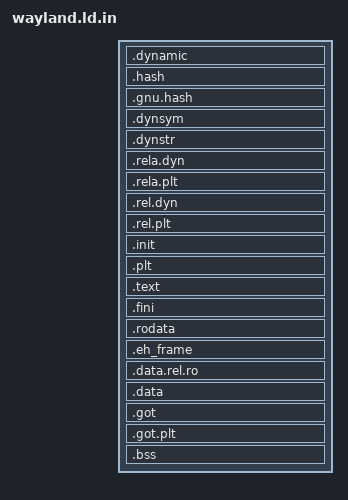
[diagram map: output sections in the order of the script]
/*
 * Linker script template for the CactOS Wayland libraries.  meson substitutes
 * @base@ per library (the loader's library slab; the whole address map is in
 * CactLibc ldso/ldso.h).  CactOS maps every image at its link-time address
 * (bias 0), so each base only has to be disjoint from every other image and
 * below the kernel mmap window (0x80000000).
 */

SECTIONS {
    . = @base@;

    .dynamic   : { *(.dynamic) }
    .hash      : { *(.hash) }
    .gnu.hash  : { *(.gnu.hash) }
    .dynsym    : { *(.dynsym) }
    .dynstr    : { *(.dynstr) }
    .rela.dyn  : { *(.rela.dyn) }
    .rela.plt  : { *(.rela.plt) }
    .rel.dyn   : { *(.rel.dyn) }
    .rel.plt   : { *(.rel.plt) }

    .init      : { *(.init) }
    .plt       : { *(.plt) }
    .text      : { *(.text .text.*) }
    .fini      : { *(.fini) }

    .rodata    : { *(.rodata .rodata.*) }
    .eh_frame  : { *(.eh_frame) }

    . = ALIGN(0x1000);
    .data.rel.ro : { *(.data.rel.ro .data.rel.ro.*) }
    .data      : { *(.data .data.*) }
    .got       : { *(.got) }
    .got.plt   : { *(.got.plt) }
    .bss       : { *(.bss .bss.*) *(COMMON) }
}
